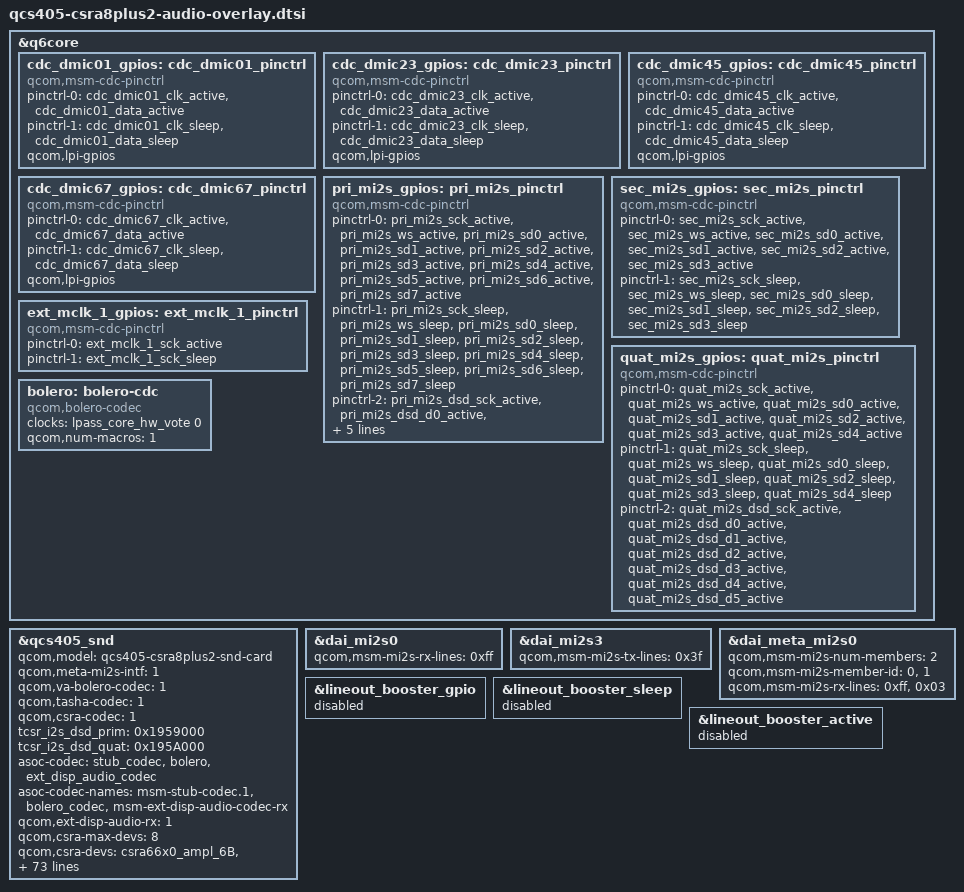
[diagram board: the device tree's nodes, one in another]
/*
 * Copyright (c) 2018-2020, The Linux Foundation. All rights reserved.
 *
 * This program is free software; you can redistribute it and/or modify
 * it under the terms of the GNU General Public License version 2 and
 * only version 2 as published by the Free Software Foundation.
 *
 * This program is distributed in the hope that it will be useful,
 * but WITHOUT ANY WARRANTY; without even the implied warranty of
 * MERCHANTABILITY or FITNESS FOR A PARTICULAR PURPOSE.  See the
 * GNU General Public License for more details.
 */

&q6core {
	cdc_dmic01_gpios: cdc_dmic01_pinctrl {
		compatible = "qcom,msm-cdc-pinctrl";
		pinctrl-names = "aud_active", "aud_sleep";
		pinctrl-0 = <&cdc_dmic01_clk_active &cdc_dmic01_data_active>;
		pinctrl-1 = <&cdc_dmic01_clk_sleep &cdc_dmic01_data_sleep>;
		qcom,lpi-gpios;
	};

	cdc_dmic23_gpios: cdc_dmic23_pinctrl {
		compatible = "qcom,msm-cdc-pinctrl";
		pinctrl-names = "aud_active", "aud_sleep";
		pinctrl-0 = <&cdc_dmic23_clk_active &cdc_dmic23_data_active>;
		pinctrl-1 = <&cdc_dmic23_clk_sleep &cdc_dmic23_data_sleep>;
		qcom,lpi-gpios;
	};

	cdc_dmic45_gpios: cdc_dmic45_pinctrl {
		compatible = "qcom,msm-cdc-pinctrl";
		pinctrl-names = "aud_active", "aud_sleep";
		pinctrl-0 = <&cdc_dmic45_clk_active &cdc_dmic45_data_active>;
		pinctrl-1 = <&cdc_dmic45_clk_sleep &cdc_dmic45_data_sleep>;
		qcom,lpi-gpios;
	};

	cdc_dmic67_gpios: cdc_dmic67_pinctrl {
		compatible = "qcom,msm-cdc-pinctrl";
		pinctrl-names = "aud_active", "aud_sleep";
		pinctrl-0 = <&cdc_dmic67_clk_active &cdc_dmic67_data_active>;
		pinctrl-1 = <&cdc_dmic67_clk_sleep &cdc_dmic67_data_sleep>;
		qcom,lpi-gpios;
	};

	pri_mi2s_gpios: pri_mi2s_pinctrl {
		compatible = "qcom,msm-cdc-pinctrl";
		pinctrl-names = "aud_active", "aud_sleep", "aud_alt_active";
		pinctrl-0 = <&pri_mi2s_sck_active &pri_mi2s_ws_active
		&pri_mi2s_sd0_active &pri_mi2s_sd1_active
		&pri_mi2s_sd2_active &pri_mi2s_sd3_active
		&pri_mi2s_sd4_active &pri_mi2s_sd5_active
		&pri_mi2s_sd6_active &pri_mi2s_sd7_active>;
		pinctrl-1 = <&pri_mi2s_sck_sleep &pri_mi2s_ws_sleep
		&pri_mi2s_sd0_sleep &pri_mi2s_sd1_sleep
		&pri_mi2s_sd2_sleep &pri_mi2s_sd3_sleep
		&pri_mi2s_sd4_sleep &pri_mi2s_sd5_sleep
		&pri_mi2s_sd6_sleep &pri_mi2s_sd7_sleep>;
		pinctrl-2 = <&pri_mi2s_dsd_sck_active &pri_mi2s_dsd_d0_active
		&pri_mi2s_dsd_d1_active &pri_mi2s_dsd_d2_active
		&pri_mi2s_dsd_d3_active &pri_mi2s_dsd_d4_active
		&pri_mi2s_dsd_d5_active>;
	};

	sec_mi2s_gpios: sec_mi2s_pinctrl {
		compatible = "qcom,msm-cdc-pinctrl";
		pinctrl-names = "aud_active", "aud_sleep";
		pinctrl-0 = <&sec_mi2s_sck_active &sec_mi2s_ws_active
		&sec_mi2s_sd0_active &sec_mi2s_sd1_active
		&sec_mi2s_sd2_active &sec_mi2s_sd3_active>;
		pinctrl-1 = <&sec_mi2s_sck_sleep &sec_mi2s_ws_sleep
		&sec_mi2s_sd0_sleep &sec_mi2s_sd1_sleep
		&sec_mi2s_sd2_sleep &sec_mi2s_sd3_sleep>;
	};

	quat_mi2s_gpios: quat_mi2s_pinctrl {
		compatible = "qcom,msm-cdc-pinctrl";
		pinctrl-names = "aud_active", "aud_sleep", "aud_alt_active";
		pinctrl-0 = <&quat_mi2s_sck_active &quat_mi2s_ws_active
		&quat_mi2s_sd0_active &quat_mi2s_sd1_active
		&quat_mi2s_sd2_active &quat_mi2s_sd3_active
		&quat_mi2s_sd4_active>;
		pinctrl-1 = <&quat_mi2s_sck_sleep &quat_mi2s_ws_sleep
		&quat_mi2s_sd0_sleep &quat_mi2s_sd1_sleep
		&quat_mi2s_sd2_sleep &quat_mi2s_sd3_sleep
		&quat_mi2s_sd4_sleep>;
		pinctrl-2 = <&quat_mi2s_dsd_sck_active &quat_mi2s_dsd_d0_active
		&quat_mi2s_dsd_d1_active &quat_mi2s_dsd_d2_active
		&quat_mi2s_dsd_d3_active &quat_mi2s_dsd_d4_active
		&quat_mi2s_dsd_d5_active>;
	};

	ext_mclk_1_gpios: ext_mclk_1_pinctrl {
		compatible = "qcom,msm-cdc-pinctrl";
		pinctrl-names = "aud_active", "aud_sleep";
		pinctrl-0 = <&ext_mclk_1_sck_active>;
		pinctrl-1 = <&ext_mclk_1_sck_sleep>;
	};
};

&q6core {
	bolero: bolero-cdc {
		compatible = "qcom,bolero-codec";
		clock-names = "lpass_core_hw_vote";
		clocks = <&lpass_core_hw_vote 0>;
		qcom,num-macros = <1>;
	};
};

&qcs405_snd {
	qcom,model = "qcs405-csra8plus2-snd-card";
	qcom,meta-mi2s-intf = <1>;
	qcom,va-bolero-codec = <1>;
	qcom,tasha-codec = <1>;
	qcom,csra-codec = <1>;
	tcsr_i2s_dsd_prim = <0x1959000>;
	tcsr_i2s_dsd_quat = <0x195A000>;
	asoc-codec = <&stub_codec>, <&bolero>;
	asoc-codec-names = "msm-stub-codec.1", "bolero_codec";
	qcom,ext-disp-audio-rx = <1>;
	asoc-codec = <&stub_codec>, <&bolero>, <&ext_disp_audio_codec>;
	asoc-codec-names = "msm-stub-codec.1", "bolero_codec",
		"msm-ext-disp-audio-codec-rx";
	qcom,csra-max-devs = <8>;
	qcom,csra-devs = <&csra66x0_ampl_6B>, <&csra66x0_ampl_6A>,
		<&csra66x0_ampl_69>, <&csra66x0_ampl_68>,
		<&csra66x0_ampl_6B_1>, <&csra66x0_ampl_6A_1>,
		<&csra66x0_ampl_69_1>, <&csra66x0_ampl_68_1>;
	qcom,csra-aux-dev-prefix = "CSRA_78", "CSRA_56", "CSRA_34",
		"CSRA_12", "CSRA_F0", "CSRA_DE", "CSRA_BC", "CSRA_9A";
	qcom,cdc-dmic01-gpios = <&cdc_dmic01_gpios>;
	qcom,cdc-dmic23-gpios = <&cdc_dmic23_gpios>;
	qcom,cdc-dmic45-gpios = <&cdc_dmic45_gpios>;
	qcom,cdc-dmic67-gpios = <&cdc_dmic67_gpios>;
	qcom,pri-mi2s-gpios = <&pri_mi2s_gpios>;
	qcom,sec-mi2s-gpios = <&sec_mi2s_gpios>;
	qcom,quat-mi2s-gpios = <&quat_mi2s_gpios>;
	qcom,msm-mi2s-master = <1>, <0>, <1>, <0>, <1>, <1>;
	qcom,audio-routing =
		"RX_BIAS", "MCLK",
		"lineout booster", "LINEOUT1",
		"lineout booster", "LINEOUT2",
		"LINEOUT1", "rx regulator",
		"LINEOUT2", "rx regulator",
		"AMIC3", "tx regulator",
		"AMIC4", "tx regulator",
		"AMIC3", "MIC BIAS3",
		"AMIC4", "MIC BIAS4",
		"MIC BIAS3", "Analog Mic3",
		"MIC BIAS4", "Analog Mic4",
		"VA DMIC0", "VA MIC BIAS1",
		"VA MIC BIAS1", "Digital Mic0",
		"VA DMIC1", "VA MIC BIAS1",
		"VA MIC BIAS1", "Digital Mic1",
		"VA DMIC2", "VA MIC BIAS1",
		"VA MIC BIAS1", "Digital Mic2",
		"VA DMIC3", "VA MIC BIAS1",
		"VA MIC BIAS1", "Digital Mic3",
		"VA DMIC4", "VA MIC BIAS1",
		"VA MIC BIAS1", "Digital Mic4",
		"VA DMIC5", "VA MIC BIAS1",
		"VA MIC BIAS1", "Digital Mic5",
		"VA DMIC6", "VA MIC BIAS1",
		"VA MIC BIAS1", "Digital Mic6",
		"VA DMIC7", "VA MIC BIAS1",
		"VA MIC BIAS1", "Digital Mic7",
		"CSRA_12 IN", "PRI_META_MI2S_RX",
		"CSRA_34 IN", "PRI_META_MI2S_RX",
		"CSRA_56 IN", "PRI_META_MI2S_RX",
		"CSRA_78 IN", "PRI_META_MI2S_RX",
		"CSRA_9A IN", "PRI_META_MI2S_RX",
		"CSRA_BC IN", "PRI_META_MI2S_RX",
		"CSRA_DE IN", "PRI_META_MI2S_RX",
		"CSRA_F0 IN", "PRI_META_MI2S_RX";
	pinctrl-names = "default";
	pinctrl-0 = <&spdifrx_opt_default>;

	qcom,ext-mclk-gpio = <&ext_mclk_1_gpios>;
	qcom,ext-mclk-src = <&ep92a6_hdmi_64>;
	#ext-mclk-1-cfg-cells = <6>;
	ext-mclk-1-cfg-11p2896 =
		<  352800    2    1   32   32    3>,
		<  705600    2    1   16   16    3>,
		< 1411200    2    1    8    8    3>,
		< 2822400    8    0    0    0    3>,
		< 5644800    4    0    0    0    3>,
		<11289600    2    0    0    0    3>,
		<22579200    2    2    1    1    3>;
	ext-mclk-1-cfg-12p288 =
		<  256000    2    1   48   48    3>,
		<  384000    2    1   32   32    3>,
		<  512000    2    2   48   48    3>,
		<  768000    2    1   16   16    3>,
		< 1024000    2    1   12   12    3>,
		< 1536000    2    1    8    8    3>,
		< 2048000   12    0    0    0    3>,
		< 3072000    8    0    0    0    3>,
		< 4096000    6    0    0    0    3>,
		< 6144000    4    0    0    0    3>,
		< 8192000    6    2    1    1    3>,
		<12288000   10   10    1    1    3>,
		<15360000   20   25    2    2    3>,
		<24576000   20   20    1    1    3>;
	ext-mclk-1-cfg-16p384 =
		<  256000   32    1    4    4    3>,
		<  384000   32    3    8    8    3>,
		<  512000   32    1    2    2    3>,
		<  768000   32    3    4    4    3>,
		< 1024000   32    0    0    0    3>,
		< 1536000   24    9    8    8    3>,
		< 2048000   16    0    0    0    3>,
		< 3072000   16    3    2    2    3>,
		< 4096000    8    0    0    0    3>,
		< 6144000    8    3    2    2    3>,
		< 8192000    4    0    0    0    3>,
		<12288000    8    3    1    1    3>,
		<24576000    4    3    1    1    3>;
	ext-mclk-1-cfg-22p5792 =
		<  352800    2    1   64   64    3>,
		<  705600    2    1   32   32    3>,
		< 1411200    2    1   16   16    3>,
		< 2822400   16    0    0    0    3>,
		< 5644800    8    0    0    0    3>,
		<11289600    4    0    0    0    3>,
		<22579200    2    0    0    0    3>;
	ext-mclk-1-cfg-24p576 =
		<  256000    2    1   96   96    3>,
		<  384000    2    1   64   64    3>,
		<  512000    2    1   48   48    3>,
		<  768000    2    1   32   32    3>,
		< 1024000    2    1   24   24    3>,
		< 1536000    2    1   16   16    3>,
		< 2048000   24    0    0    0    3>,
		< 3072000   16    0    0    0    3>,
		< 4096000   12    0    0    0    3>,
		< 6144000    8    0    0    0    3>,
		< 8192000    6    0    0    0    3>,
		<12288000    4    0    0    0    3>,
		<24576000    2    0    0    0    3>;
};

&dai_mi2s0 {
	qcom,msm-mi2s-rx-lines = <0xff>;
};

&dai_mi2s3 {
	qcom,msm-mi2s-tx-lines = <0x3f>;
};

&dai_meta_mi2s0 {
	qcom,msm-mi2s-num-members =  <2>;
	qcom,msm-mi2s-member-id =  <0>, <1>;
	qcom,msm-mi2s-rx-lines = <0xff>, <0x03>;
};

#include "qcs405-tasha.dtsi"
#include "qcs405-va-bolero.dtsi"
#include "qcs405-csra8.dtsi"

&lineout_booster_gpio {
	status = "disabled";
};

&lineout_booster_sleep {
	status = "disabled";
};

&lineout_booster_active {
	status = "disabled";
};
